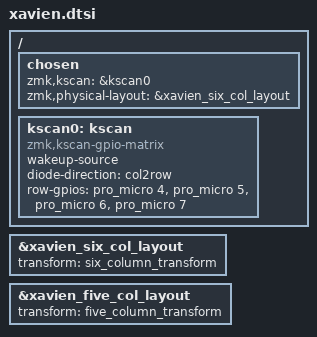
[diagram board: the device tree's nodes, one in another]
/*
 * Copyright (c) 2020 The ZMK Contributors
 *
 * SPDX-License-Identifier: MIT
 */

#include <dt-bindings/zmk/matrix_transform.h>
#include "layouts/layouts.dtsi"


&xavien_six_col_layout {
    transform = <&six_column_transform>;
};

&xavien_five_col_layout {
    transform = <&five_column_transform>;
};

/ {

	chosen {
		zmk,kscan = &kscan0;
    		zmk,physical-layout = &xavien_six_col_layout;
	};


	kscan0: kscan {
		compatible = "zmk,kscan-gpio-matrix";
		wakeup-source;

		diode-direction = "col2row";
		row-gpios
			= <&pro_micro 4 (GPIO_ACTIVE_HIGH | GPIO_PULL_DOWN)>
			, <&pro_micro 5 (GPIO_ACTIVE_HIGH | GPIO_PULL_DOWN)>
			, <&pro_micro 6 (GPIO_ACTIVE_HIGH | GPIO_PULL_DOWN)>
			, <&pro_micro 7 (GPIO_ACTIVE_HIGH | GPIO_PULL_DOWN)>
			;
	};

	// TODO: per-key RGB node(s)?
};
